AUTOSAR XML (schema 4.0)
standard types defined: float32, float64, sint16, sint32, sint8, uint16, uint32, uint8, void, boolean
package /ImplDataTypes
  5 x impl type, all with category=TYPE_REFERENCE, type-emitter=RTE:
    Impl_IOPositionSensorRead: implementation-data-type=uint8
    Impl_IOWeightSensorRead: implementation-data-type=uint16
    Impl_SeatModeButtonType: implementation-data-type=Impl_IOPositionSensorRead
    Impl_StepMotorStepSize: implementation-data-type=uint8
    MultiButtonStateType: implementation-data-type=uint8
package /MappingSets
  data type mapping set MappingSet: mode-request-type-map{implementation-data-type=uint8, mode-group=HMI_SeatManager}
package /PortInterfaces/ClientServer
  24 x client server interface:
    CsIf_HeightIsUpdated
      operation Opr_IsUpdated
    CsIf_HeightMotor
      operation Opr_IOSetForward
        arg Step: type=Impl_StepMotorStepSize, direction=IN
      operation Opr_IOSetReverse
        arg Step: type=Impl_StepMotorStepSize, direction=IN
    CsIf_HeightMotorSeatManager
      operation Opr_GetPosition
        arg Arg_Position: type=Impl_IOPositionSensorRead, direction=IN
    CsIf_HeightSensor
      operation Opr_HeightSensorGetPosition
        arg Position: type=Impl_IOPositionSensorRead, direction=OUT
    CsIf_IOHwAbsHeight
      operation Opr_HeightSensorGetPosition
        arg Arg_Height: type=Impl_IOPositionSensorRead, direction=OUT
    CsIf_IOHwAbsHeightMotor
      operation Opr_HeightMotorForward
    CsIf_IOHwAbsHeightMotorReverse
      operation Opr_HeightMotorReverse
    CsIf_IOHwAbsIncline
      operation Opr_IOHwAbsIncline
        arg Arg_Incline: type=Impl_IOPositionSensorRead, direction=OUT
    CsIf_IOHwAbsInclineMotor
      operation Opr_InclineMotorForward
    CsIf_IOHwAbsInclineMotorReverse
      operation Opr_InclineMotorReverse
    CsIf_IOHwAbsSlide
      operation Opr_IOHwAbsSlide
        arg Arg_Slide: type=Impl_IOPositionSensorRead, direction=OUT
    CsIf_IOHwAbsSlideMotor
      operation Opr_SLideMotorForward
    CsIf_IOHwAbsSlideMotorReverse
      operation Opr_SlideMotorReverse
    CsIf_IOHwAbsWeight
      operation Opr_GetWeight
        arg Arg_Weight: type=Impl_IOWeightSensorRead, direction=OUT
    CsIf_InclineIsUpdated
      operation Opr_InclineIsUpdated
    CsIf_InclineMotor
      operation Opr_InclineMotorIOSetForward
        arg Step: type=Impl_StepMotorStepSize, direction=IN
      operation Opr_InclineMotorIOSetReverse
        arg Step: type=Impl_StepMotorStepSize, direction=IN
    CsIf_InclineMotorSeatManager
      operation Opr_GetPosition
        arg Arg_Position: type=Impl_IOPositionSensorRead, direction=IN
    CsIf_InclineSensor
      operation Opr_InclineSensorGetPosition
        arg Arg_Position: type=uint8, direction=OUT
    CsIf_SeatModeButton
      operation Opr_SeatMode
        arg Arg_SeatModeButton: type=Impl_SeatModeButtonType, direction=OUT
    CsIf_SlideIsUpdated
      operation Opr_SlideIsUpdated
    CsIf_SlideMotor
      operation Opr_SlideMotorSetReverse
        arg Step: type=Impl_StepMotorStepSize, direction=IN
      operation Opr_SlideMotor_SetForrward
        arg Step: type=Impl_StepMotorStepSize, direction=IN
    CsIf_SlideMotorSeatManager
      operation Opr_GetPositon
        arg Arg_Position: type=Impl_IOPositionSensorRead, direction=IN
    CsIf_SlideSensor
      operation Opr_GetPositon
        arg Position: type=uint8, direction=OUT
    CsIf_WeightSensor
      operation Opr_GetWeight
        arg Arg_weight: type=uint16, direction=OUT
package /PortInterfaces/ModeSwitch
  mode declaration group HMI_SeatManager: category=ALPHABETIC_ORDER, initial-mode=INIT, on-transition-value=255
    mode INIT
    mode Mode_Auto
    mode Mode_Manual
  mode switch interface MsIf_HMI_SeatManager
    mode group HMI_SeatManager: type=HMI_SeatManager
package /PortInterfaces/SenderReceiver
  6 x sender receiver interface:
    SrIf_HeightBtnState
      data DE_Height: type=MultiButtonStateType
    SrIf_InclineBtnState
      data DE_Incline: type=MultiButtonStateType
    SrIf_SeatCtrlDataHeight
      data Height: type=uint8
    SrIf_SeatCtrlDataIncline
      data Incline: type=uint8
    SrIf_SeatCtrlDataSlide
      data Slide: type=uint8
    SrIf_SlideBtnState
      data DE_Slide: type=MultiButtonStateType
package /SoftwareComponents
  11 x swc implementation, all with programming-language=C, sw-version=1.0.0, vendor-id=255:
    Impl_SWC_ECU: behavior=Ibhv_SWC_ECU
      code-descriptors:
        code Code: artifact-descriptors=autosar-engineering-object={short-label=SWC.c, category=SWSRC}
      resource consumption ResourceConsumption
    Impl_SWC_HMI: behavior=Ibhv_SWC_HMI
      code-descriptors:
        code Code: artifact-descriptors=autosar-engineering-object={short-label=SWC.c, category=SWSRC}
      resource consumption ResourceConsumption
    Impl_SWC_HeightMotor: behavior=Ibhv_SWC_HeightMotor
      code-descriptors:
        code Code: artifact-descriptors=autosar-engineering-object={short-label=SWC.c, category=SWSRC}
      resource consumption ResourceConsumption
    Impl_SWC_HeightSensor: behavior=Ibhv_SWC_HeightSensor
      code-descriptors:
        code Code: artifact-descriptors=autosar-engineering-object={short-label=SWC.c, category=SWSRC}
      resource consumption ResourceConsumption
    Impl_SWC_IOHwAbs: behavior=Ibhv_SWC_IOHwAbs
      code-descriptors:
        code Code: artifact-descriptors=autosar-engineering-object={short-label=SWC.c, category=SWSRC}
      resource consumption ResourceConsumption
    Impl_SWC_InclineMotor: behavior=Ibhv_SWC_InclineMotor
      code-descriptors:
        code Code: artifact-descriptors=autosar-engineering-object={short-label=SWC.c, category=SWSRC}
      resource consumption ResourceConsumption
    Impl_SWC_InclineSensor: behavior=Ibhv_SWC_InclineSensor
      code-descriptors:
        code Code: artifact-descriptors=autosar-engineering-object={short-label=SWC.c, category=SWSRC}
      resource consumption ResourceConsumption
    Impl_SWC_SeatManager: behavior=Ibhv_SWC_SeatManager
      code-descriptors:
        code Code: artifact-descriptors=autosar-engineering-object={short-label=SWC.c, category=SWSRC}
      resource consumption ResourceConsumption
    Impl_SWC_SlideMotor: behavior=Ibhv_SWC_SlideMotor
      code-descriptors:
        code Code: artifact-descriptors=autosar-engineering-object={short-label=SWC.c, category=SWSRC}
      resource consumption ResourceConsumption
    Impl_SWC_SlideSensor: behavior=Ibhv_SWC_SlideSensor
      code-descriptors:
        code Code: artifact-descriptors=autosar-engineering-object={short-label=SWC.c, category=SWSRC}
      resource consumption ResourceConsumption
    Impl_SWC_WeightSensor: behavior=Ibhv_SWC_WeightSensor
      code-descriptors:
        code Code: artifact-descriptors=autosar-engineering-object={short-label=SWC.c, category=SWSRC}
      resource consumption ResourceConsumption
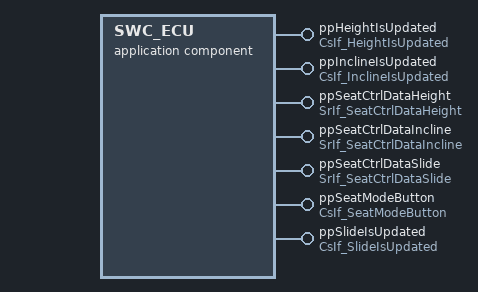
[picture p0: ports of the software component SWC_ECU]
  application sw component type SWC_ECU
    7 x provide port:
      ppHeightIsUpdated: provided-interface=CsIf_HeightIsUpdated
      ppInclineIsUpdated: provided-interface=CsIf_InclineIsUpdated
      ppSeatCtrlDataHeight: provided-interface=SrIf_SeatCtrlDataHeight
      ppSeatCtrlDataIncline: provided-interface=SrIf_SeatCtrlDataIncline
      ppSeatCtrlDataSlide: provided-interface=SrIf_SeatCtrlDataSlide
      ppSeatModeButton: provided-interface=CsIf_SeatModeButton
      ppSlideIsUpdated: provided-interface=CsIf_SlideIsUpdated
    behavior Ibhv_SWC_ECU: data-type-mapping=MappingSet, handle-termination-and-restart=NO-SUPPORT
      4 x operation invoked event:
        OIE_ppHeightIsUpdated_Opr_IsUpdated: start-on-event=RE_IsUpdated, operation=ppHeightIsUpdated.Opr_IsUpdated
        OIE_ppInclineIsUpdated_Opr_InclineIsUpdated: start-on-event=RE_InclineIsUpdated, operation=ppInclineIsUpdated.Opr_InclineIsUpdated
        OIE_ppSeatModeButton_Opr_SeatMode: start-on-event=RE_HMISeatModeManager, operation=ppSeatModeButton.Opr_SeatMode
        OIE_ppSlideIsUpdated_Opr_SlideIsUpdated: start-on-event=RE_SlideIsUpdated, operation=ppSlideIsUpdated.Opr_SlideIsUpdated
      4 x runnable:
        RE_HMISeatModeManager
        RE_InclineIsUpdated
        RE_IsUpdated
        RE_SlideIsUpdated
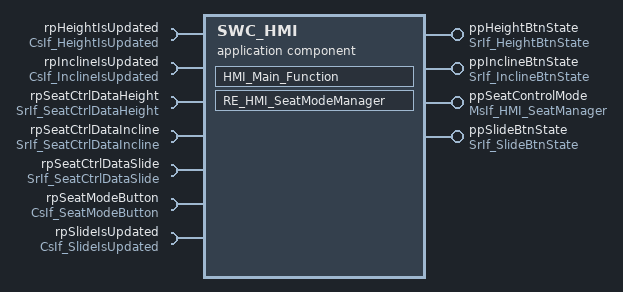
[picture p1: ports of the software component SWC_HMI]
  application sw component type SWC_HMI
    4 x provide port:
      ppHeightBtnState: provided-interface=SrIf_HeightBtnState
      ppInclineBtnState: provided-interface=SrIf_InclineBtnState
      ppSeatControlMode: provided-interface=MsIf_HMI_SeatManager
      ppSlideBtnState: provided-interface=SrIf_SlideBtnState
    7 x require port:
      rpHeightIsUpdated: required-interface=CsIf_HeightIsUpdated
      rpInclineIsUpdated: required-interface=CsIf_InclineIsUpdated
      rpSeatCtrlDataHeight: required-interface=SrIf_SeatCtrlDataHeight
      rpSeatCtrlDataIncline: required-interface=SrIf_SeatCtrlDataIncline
      rpSeatCtrlDataSlide: required-interface=SrIf_SeatCtrlDataSlide
      rpSeatModeButton: required-interface=CsIf_SeatModeButton
      rpSlideIsUpdated: required-interface=CsIf_SlideIsUpdated
    behavior Ibhv_SWC_HMI: data-type-mapping=MappingSet, handle-termination-and-restart=NO-SUPPORT
      runnable HMI_Main_Function
        data-receive-point-by-arguments:
          access DRP_rpSeatCtrlDataHeight_Height: accessed-variable=rpSeatCtrlDataHeight.Height
          access DRP_rpSeatCtrlDataIncline_Incline: accessed-variable=rpSeatCtrlDataIncline.Incline
          access DRP_rpSeatCtrlDataSlide_Slide: accessed-variable=rpSeatCtrlDataSlide.Slide
        data-send-points:
          access DSP_ppHeightBtnState_DE_Height: accessed-variable=ppHeightBtnState.DE_Height
          access DSP_ppInclineBtnState_DE_Incline: accessed-variable=ppInclineBtnState.DE_Incline
          access DSP_ppSlideBtnState_DE_Slide: accessed-variable=ppSlideBtnState.DE_Slide
        sync call SCP_rpHeightIsUpdated_Opr_IsUpdated: operation=rpHeightIsUpdated.Opr_IsUpdated, timeout=0.0
        sync call SCP_rpInclineIsUpdated_Opr_InclineIsUpdated: operation=rpInclineIsUpdated.Opr_InclineIsUpdated, timeout=0.0
        sync call SCP_rpSlideIsUpdated_Opr_SlideIsUpdated: operation=rpSlideIsUpdated.Opr_SlideIsUpdated, timeout=0.0
      runnable RE_HMI_SeatModeManager
        mode switch point MSP_ppSeatControlMode_ppSeatControlMode: mode-group=ppSeatControlMode.HMI_SeatManager
        sync call SCP_rpSeatModeButton_Opr_SeatMode: operation=rpSeatModeButton.Opr_SeatMode, timeout=0.0
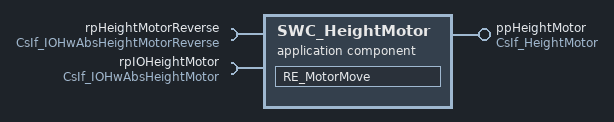
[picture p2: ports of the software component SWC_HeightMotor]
  application sw component type SWC_HeightMotor
    provide port ppHeightMotor: provided-interface=CsIf_HeightMotor
    require port rpHeightMotorReverse: required-interface=CsIf_IOHwAbsHeightMotorReverse
    require port rpIOHeightMotor: required-interface=CsIf_IOHwAbsHeightMotor
    behavior Ibhv_SWC_HeightMotor: data-type-mapping=MappingSet, handle-termination-and-restart=NO-SUPPORT
      operation invoked event OIE_ppHeightMotor_Opr_IOSetForward: start-on-event=RE_MotorMove, operation=ppHeightMotor.Opr_IOSetForward
      operation invoked event OIE_ppHeightMotor_Opr_IOSetReverse: start-on-event=RE_MotorMove, operation=ppHeightMotor.Opr_IOSetReverse
      runnable RE_MotorMove
        sync call SCP_rpHeightMotorReverse_Opr_HeightMotorReverse: operation=rpHeightMotorReverse.Opr_HeightMotorReverse, timeout=0.0
        sync call SCP_rpIOHeightMotor_Opr_HeightMotorForward: operation=rpIOHeightMotor.Opr_HeightMotorForward, timeout=0.0
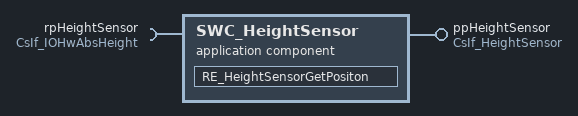
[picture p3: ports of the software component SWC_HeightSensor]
  application sw component type SWC_HeightSensor
    provide port ppHeightSensor: provided-interface=CsIf_HeightSensor
    require port rpHeightSensor: required-interface=CsIf_IOHwAbsHeight
    behavior Ibhv_SWC_HeightSensor: data-type-mapping=MappingSet, handle-termination-and-restart=NO-SUPPORT
      operation invoked event OIE_ppHeightSensor_Opr_HeightSensorGetPosition: start-on-event=Ibhv_SWC_HeightSensor/RE_HeightSensorGetPositon, operation=ppHeightSensor.Opr_HeightSensorGetPosition
      runnable RE_HeightSensorGetPositon
        sync call SCP_rpHeightSensor_Opr_GetHeight: operation=rpHeightSensor.Opr_HeightSensorGetPosition, timeout=0.0
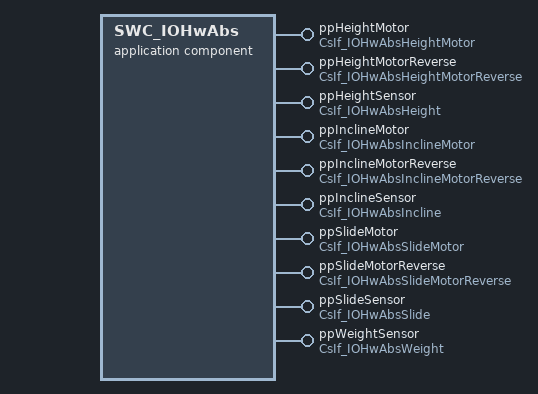
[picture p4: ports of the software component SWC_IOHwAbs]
  application sw component type SWC_IOHwAbs
    10 x provide port:
      ppHeightMotor: provided-interface=CsIf_IOHwAbsHeightMotor
      ppHeightMotorReverse: provided-interface=CsIf_IOHwAbsHeightMotorReverse
      ppHeightSensor: provided-interface=CsIf_IOHwAbsHeight
      ppInclineMotor: provided-interface=CsIf_IOHwAbsInclineMotor
      ppInclineMotorReverse: provided-interface=CsIf_IOHwAbsInclineMotorReverse
      ppInclineSensor: provided-interface=CsIf_IOHwAbsIncline
      ppSlideMotor: provided-interface=CsIf_IOHwAbsSlideMotor
      ppSlideMotorReverse: provided-interface=CsIf_IOHwAbsSlideMotorReverse
      ppSlideSensor: provided-interface=CsIf_IOHwAbsSlide
      ppWeightSensor: provided-interface=CsIf_IOHwAbsWeight
    behavior Ibhv_SWC_IOHwAbs: data-type-mapping=MappingSet, handle-termination-and-restart=NO-SUPPORT
      10 x operation invoked event:
        OIE_ppHeightMotorReverse_Opr_HeightMotorReverse: start-on-event=RE_HeightMotorSetReverse, operation=ppHeightMotorReverse.Opr_HeightMotorReverse
        OIE_ppHeightMotor_Opr_HeightMotorForward: start-on-event=RE_HeightMotorSetForward, operation=ppHeightMotor.Opr_HeightMotorForward
        OIE_ppHeightSensor_Opr_HeightSensorGetPosition: start-on-event=Ibhv_SWC_IOHwAbs/RE_HeightSensorGetPositon, operation=ppHeightSensor.Opr_HeightSensorGetPosition
        OIE_ppInclineMotorReverse_Opr_InclineMotorReverse: start-on-event=RE_InclineMotorSetReverse, operation=ppInclineMotorReverse.Opr_InclineMotorReverse
        OIE_ppInclineMotor_Opr_InclineMotorForward: start-on-event=RE_InclineMotorSetForward, operation=ppInclineMotor.Opr_InclineMotorForward
        OIE_ppInclineSensor_Opr_IOHwAbsIncline: start-on-event=RE_InclineSensorGetPosition, operation=ppInclineSensor.Opr_IOHwAbsIncline
        OIE_ppSlideMotorReverse_Opr_SlideMotorReverse: start-on-event=RE_SlideMotorSetReverse, operation=ppSlideMotorReverse.Opr_SlideMotorReverse
        OIE_ppSlideMotor_Opr_SLideMotorForward: start-on-event=RE_SlideMotorSetForward, operation=ppSlideMotor.Opr_SLideMotorForward
        OIE_ppSlideSensor_Opr_IOHwAbsSlide: start-on-event=RE_SlideSensorGetPosition, operation=ppSlideSensor.Opr_IOHwAbsSlide
        OIE_ppWeightSensor_Opr_GetWeight: start-on-event=RE_IoHwAbsGetWeight, operation=ppWeightSensor.Opr_GetWeight
      10 x runnable:
        RE_HeightMotorSetForward
        RE_HeightMotorSetReverse
        RE_HeightSensorGetPositon
        RE_InclineMotorSetForward
        RE_InclineMotorSetReverse
        RE_InclineSensorGetPosition
        RE_IoHwAbsGetWeight
        RE_SlideMotorSetForward
        RE_SlideMotorSetReverse
        RE_SlideSensorGetPosition
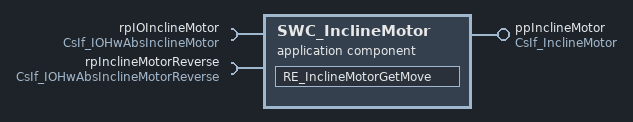
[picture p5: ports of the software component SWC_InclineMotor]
  application sw component type SWC_InclineMotor
    provide port ppInclineMotor: provided-interface=CsIf_InclineMotor
    require port rpIOInclineMotor: required-interface=CsIf_IOHwAbsInclineMotor
    require port rpInclineMotorReverse: required-interface=CsIf_IOHwAbsInclineMotorReverse
    behavior Ibhv_SWC_InclineMotor: data-type-mapping=MappingSet, handle-termination-and-restart=NO-SUPPORT
      operation invoked event OIE_ppInclineMotor_Opr_InclineMotorIOSetForward: start-on-event=RE_InclineMotorGetMove, operation=ppInclineMotor.Opr_InclineMotorIOSetForward
      operation invoked event OIE_ppInclineMotor_Opr_InclineMotorIOSetReverse: start-on-event=RE_InclineMotorGetMove, operation=ppInclineMotor.Opr_InclineMotorIOSetReverse
      runnable RE_InclineMotorGetMove
        sync call SCP_rpIOInclineMotor_Opr_InclineMotorForward: operation=rpIOInclineMotor.Opr_InclineMotorForward, timeout=0.0
        sync call SCP_rpInclineMotorReverse_Opr_InclineMotorReverse: operation=rpInclineMotorReverse.Opr_InclineMotorReverse, timeout=0.0
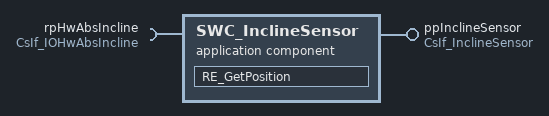
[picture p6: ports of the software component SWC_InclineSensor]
  application sw component type SWC_InclineSensor
    provide port ppInclineSensor: provided-interface=CsIf_InclineSensor
    require port rpHwAbsIncline: required-interface=CsIf_IOHwAbsIncline
    behavior Ibhv_SWC_InclineSensor: data-type-mapping=MappingSet, handle-termination-and-restart=NO-SUPPORT
      operation invoked event OIE_ppInclineSensor_Opr_InclineSensorGetPosition: start-on-event=Ibhv_SWC_InclineSensor/RE_GetPosition, operation=ppInclineSensor.Opr_InclineSensorGetPosition
      runnable RE_GetPosition
        sync call SCP_rpHwAbsIncline_Opr_IOHwAbsIncline: operation=rpHwAbsIncline.Opr_IOHwAbsIncline, timeout=0.0
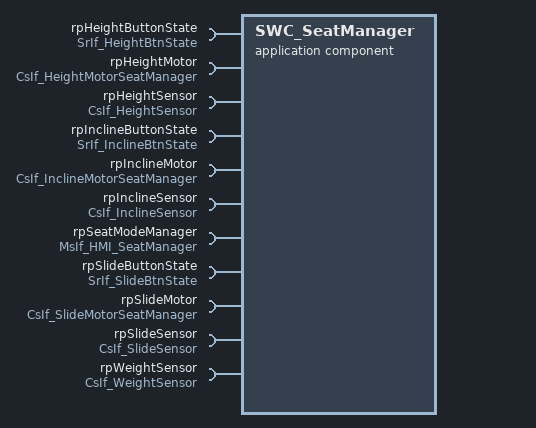
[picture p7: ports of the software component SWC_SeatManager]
  application sw component type SWC_SeatManager
    11 x require port:
      rpHeightButtonState: required-interface=SrIf_HeightBtnState
      rpHeightMotor: required-interface=CsIf_HeightMotorSeatManager
      rpHeightSensor: required-interface=CsIf_HeightSensor
      rpInclineButtonState: required-interface=SrIf_InclineBtnState
      rpInclineMotor: required-interface=CsIf_InclineMotorSeatManager
      rpInclineSensor: required-interface=CsIf_InclineSensor
      rpSeatModeManager: required-interface=MsIf_HMI_SeatManager
      rpSlideButtonState: required-interface=SrIf_SlideBtnState
      rpSlideMotor: required-interface=CsIf_SlideMotorSeatManager
      rpSlideSensor: required-interface=CsIf_SlideSensor
      rpWeightSensor: required-interface=CsIf_WeightSensor
    behavior Ibhv_SWC_SeatManager: data-type-mapping=MappingSet, handle-termination-and-restart=NO-SUPPORT
      swc mode switch event MSE_rpSeatModeManager_Mode_Auto_ON_ENTRY: start-on-event=RE_AutoHeight, activation=ON-ENTRY, mode=rpSeatModeManager.HMI_SeatManager.Mode_Auto
      swc mode switch event MSE_rpSeatModeManager_Mode_Auto_ON_ENTRY: start-on-event=RE_AutoIncline, activation=ON-ENTRY, mode=rpSeatModeManager.HMI_SeatManager.Mode_Auto
      swc mode switch event MSE_rpSeatModeManager_Mode_Auto_ON_ENTRY: start-on-event=RE_AutoSlide, activation=ON-ENTRY, mode=rpSeatModeManager.HMI_SeatManager.Mode_Auto
      6 x runnable:
        RE_AutoHeight
          sync call SCP_rpHeightMotor_Opr_GetPosition: operation=rpHeightMotor.Opr_GetPosition, timeout=0.0
          sync call SCP_rpHeightSensor_Opr_HeightSensorGetPosition: operation=rpHeightSensor.Opr_HeightSensorGetPosition, timeout=0.0
          sync call SCP_rpWeightSensor_Opr_GetWeight: operation=rpWeightSensor.Opr_GetWeight, timeout=0.0
        RE_AutoIncline
          sync call SCP_rpInclineMotor_Opr_GetPosition: operation=rpInclineMotor.Opr_GetPosition, timeout=0.0
          sync call SCP_rpInclineSensor_Opr_Position: operation=rpInclineSensor.Opr_InclineSensorGetPosition, timeout=0.0
          sync call SCP_rpWeightSensor_Opr_GetWeight: operation=rpWeightSensor.Opr_GetWeight, timeout=0.0
        RE_AutoSlide
          sync call SCP_rpSlideMotor_Opr_GetPositon: operation=rpSlideMotor.Opr_GetPositon, timeout=0.0
          sync call SCP_rpSlideSensor_Opr_GetPositon: operation=rpSlideSensor.Opr_GetPositon, timeout=0.0
          sync call SCP_rpWeightSensor_Opr_GetWeight: operation=rpWeightSensor.Opr_GetWeight, timeout=0.0
        RE_SetHeightManual
          sync call SCP_rpHeightButtonState_Opr_HeightState: operation=rpHeightButtonState.Opr_HeightState, timeout=0.0
          sync call SCP_rpHeightMotor_Opr_GetPosition: operation=rpHeightMotor.Opr_GetPosition, timeout=0.0
        RE_SetInclineManual
          sync call SCP_rpInclineButtonState_Opr_InclineBtnState: operation=rpInclineButtonState.Opr_InclineBtnState, timeout=0.0
          sync call SCP_rpInclineMotor_Opr_GetPosition: operation=rpInclineMotor.Opr_GetPosition, timeout=0.0
        RE_SetSlideManual
          sync call SCP_rpSlideButtonState_Opr_SlideButtonState: operation=rpSlideButtonState.Opr_SlideButtonState, timeout=0.0
          sync call SCP_rpSlideMotor_Opr_GetPositon: operation=rpSlideMotor.Opr_GetPositon, timeout=0.0
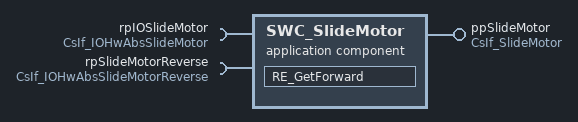
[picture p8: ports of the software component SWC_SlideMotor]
  application sw component type SWC_SlideMotor
    provide port ppSlideMotor: provided-interface=CsIf_SlideMotor
    require port rpIOSlideMotor: required-interface=CsIf_IOHwAbsSlideMotor
    require port rpSlideMotorReverse: required-interface=CsIf_IOHwAbsSlideMotorReverse
    behavior Ibhv_SWC_SlideMotor: data-type-mapping=MappingSet, handle-termination-and-restart=NO-SUPPORT
      operation invoked event OIE_ppSlideMotor_Opr_SlideMotorSetReverse: start-on-event=RE_GetForward, operation=ppSlideMotor.Opr_SlideMotorSetReverse
      operation invoked event OIE_ppSlideMotor_Opr_SlideMotor_SetForrward: start-on-event=RE_GetForward, operation=ppSlideMotor.Opr_SlideMotor_SetForrward
      runnable RE_GetForward
        sync call SCP_rpIOSlideMotor_Opr_SLideMotorForward: operation=rpIOSlideMotor.Opr_SLideMotorForward, timeout=0.0
        sync call SCP_rpSlideMotorReverse_Opr_SlideMotorReverse: operation=rpSlideMotorReverse.Opr_SlideMotorReverse, timeout=0.0
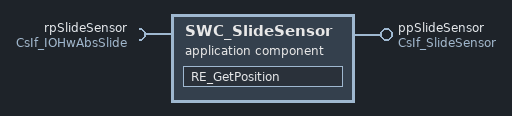
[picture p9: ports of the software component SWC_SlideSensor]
  application sw component type SWC_SlideSensor
    provide port ppSlideSensor: provided-interface=CsIf_SlideSensor
    require port rpSlideSensor: required-interface=CsIf_IOHwAbsSlide
    behavior Ibhv_SWC_SlideSensor: data-type-mapping=MappingSet, handle-termination-and-restart=NO-SUPPORT
      operation invoked event OIE_ppSlideSensor_Opr_GetPositon: start-on-event=Ibhv_SWC_SlideSensor/RE_GetPosition, operation=ppSlideSensor.Opr_GetPositon
      runnable RE_GetPosition
        sync call SCP_rpSlideSensor_Opr_IOHwAbsSlide: operation=rpSlideSensor.Opr_IOHwAbsSlide, timeout=0.0
  application sw component type SWC_WeightSensor
    provide port ppWeightSensor: provided-interface=CsIf_WeightSensor
    require port rpHwAbsWeight: required-interface=CsIf_IOHwAbsWeight
    behavior Ibhv_SWC_WeightSensor: data-type-mapping=MappingSet, handle-termination-and-restart=NO-SUPPORT
      operation invoked event OIE_ppWeightSensor_Opr_GetWeight: start-on-event=RE_GetWeight, operation=ppWeightSensor.Opr_GetWeight
      runnable RE_GetWeight
        sync call SCP_rpHwAbsWeight_Opr_GetWeight: operation=rpHwAbsWeight.Opr_GetWeight, timeout=0.0
package /Compositions
  composition sw component type TestApp5Composition
    11 x component:
      SWC_ECU: type=SWC_ECU
      SWC_HMI: type=SWC_HMI
      SWC_HeightMotor: type=SWC_HeightMotor
      SWC_HeightSensor: type=SWC_HeightSensor
      SWC_IOHwAbs: type=SWC_IOHwAbs
      SWC_InclineMotor: type=SWC_InclineMotor
      SWC_InclineSensor: type=SWC_InclineSensor
      SWC_SeatManager: type=SWC_SeatManager
      SWC_SlideMotor: type=SWC_SlideMotor
      SWC_SlideSensor: type=SWC_SlideSensor
      SWC_WeightSensor: type=SWC_WeightSensor
    connect SWC_ECU.ppHeightIsUpdated -> SWC_HMI.rpHeightIsUpdated
    connect SWC_ECU.ppInclineIsUpdated -> SWC_HMI.rpInclineIsUpdated
    connect SWC_ECU.ppSeatCtrlDataHeight -> SWC_HMI.rpSeatCtrlDataHeight
    connect SWC_ECU.ppSeatCtrlDataIncline -> SWC_HMI.rpSeatCtrlDataIncline
    connect SWC_ECU.ppSeatCtrlDataSlide -> SWC_HMI.rpSeatCtrlDataSlide
    connect SWC_ECU.ppSeatModeButton -> SWC_HMI.rpSeatModeButton
    connect SWC_ECU.ppSlideIsUpdated -> SWC_HMI.rpSlideIsUpdated
    connect SWC_HMI.ppHeightBtnState -> SWC_SeatManager.rpHeightButtonState
    connect SWC_HMI.ppInclineBtnState -> SWC_SeatManager.rpInclineButtonState
    connect SWC_HMI.ppSlideBtnState -> SWC_SeatManager.rpSlideButtonState
    connect SWC_HMI.ppSeatControlMode -> SWC_SeatManager.rpSeatModeManager
    connect SWC_HeightMotor.ppHeightMotor -> SWC_SeatManager.rpHeightMotor
    connect SWC_HeightSensor.ppHeightSensor -> SWC_SeatManager.rpHeightSensor
    connect SWC_IOHwAbs.ppHeightMotorReverse -> SWC_HeightMotor.rpHeightMotorReverse
    connect SWC_IOHwAbs.ppHeightMotor -> SWC_HeightMotor.rpIOHeightMotor
    connect SWC_IOHwAbs.ppHeightSensor -> SWC_HeightSensor.rpHeightSensor
    connect SWC_IOHwAbs.ppInclineMotorReverse -> SWC_InclineMotor.rpInclineMotorReverse
    connect SWC_IOHwAbs.ppInclineMotor -> SWC_InclineMotor.rpIOInclineMotor
    connect SWC_IOHwAbs.ppInclineSensor -> SWC_InclineSensor.rpHwAbsIncline
    connect SWC_IOHwAbs.ppSlideMotor -> SWC_SlideMotor.rpIOSlideMotor
    connect SWC_IOHwAbs.ppSlideMotor -> SWC_SlideMotor.rpSlideMotorReverse
    connect SWC_IOHwAbs.ppSlideSensor -> SWC_SlideSensor.rpSlideSensor
    connect SWC_IOHwAbs.ppWeightSensor -> SWC_WeightSensor.rpHwAbsWeight
    connect SWC_InclineMotor.ppInclineMotor -> SWC_SeatManager.rpInclineMotor
    connect SWC_InclineSensor.ppInclineSensor -> SWC_SeatManager.rpInclineSensor
    connect SWC_SlideMotor.ppSlideMotor -> SWC_SeatManager.rpSlideMotor
    connect SWC_SlideSensor.ppSlideSensor -> SWC_SeatManager.rpSlideSensor
    connect SWC_WeightSensor.ppWeightSensor -> SWC_SeatManager.rpWeightSensor
